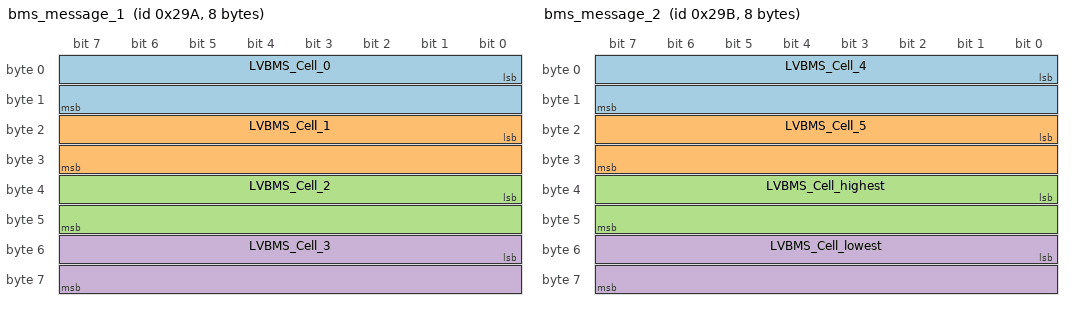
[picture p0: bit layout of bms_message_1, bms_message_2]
BO_ 666 bms_message_1: 8 LVBMS
	SG_ LVBMS_Cell_0 : 0|16@1+ (0.001,0) [0|6.5535] "V" LVBMS
	SG_ LVBMS_Cell_1 : 16|16@1+ (0.001,0) [0|6.5535] "V" LVBMS
	SG_ LVBMS_Cell_2 : 32|16@1+ (0.001,0) [0|6.5535] "V" LVBMS
	SG_ LVBMS_Cell_3 : 48|16@1+ (0.001,0) [0|6.5535] "V" LVBMS

BO_ 667 bms_message_2: 8 LVBMS
	SG_ LVBMS_Cell_4 : 0|16@1+ (0.001,0) [0|6.5535] "V" LVBMS
	SG_ LVBMS_Cell_5 : 16|16@1+ (0.001,0) [0|6.5535] "V" LVBMS
	SG_ LVBMS_Cell_highest : 32|16@1+ (0.001,0) [0|6.5535] "V" LVBMS
	SG_ LVBMS_Cell_lowest : 48|16@1+ (0.001,0) [0|6.5535] "V" LVBMS

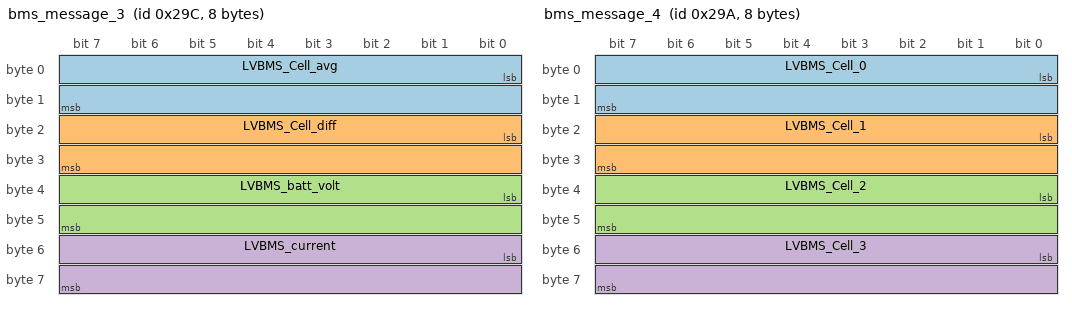
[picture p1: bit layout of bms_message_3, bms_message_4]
BO_ 668 bms_message_3: 8 LVBMS
	SG_ LVBMS_Cell_avg : 0|16@1+ (0.001,0) [0|6.5535] "V" LVBMS
	SG_ LVBMS_Cell_diff : 16|16@1+ (0.001,0) [0|6.5535] "V" LVBMS
	SG_ LVBMS_batt_volt : 32|16@1+ (0.001,0) [0|25] "V" LVBMS
	SG_ LVBMS_current : 48|16@1+ (0.001,0) [0|8] "A" LVBMS

BO_ 666 bms_message_4: 8 LVBMS
	SG_ LVBMS_Cell_0 : 0|16@1+ (0.001,0) [0|6.5535] "V" LVBMS
	SG_ LVBMS_Cell_1 : 16|16@1+ (0.001,0) [0|6.5535] "V" LVBMS
	SG_ LVBMS_Cell_2 : 32|16@1+ (0.001,0) [0|6.5535] "V" LVBMS
	SG_ LVBMS_Cell_3 : 48|16@1+ (0.001,0) [0|6.5535] "V" LVBMS
